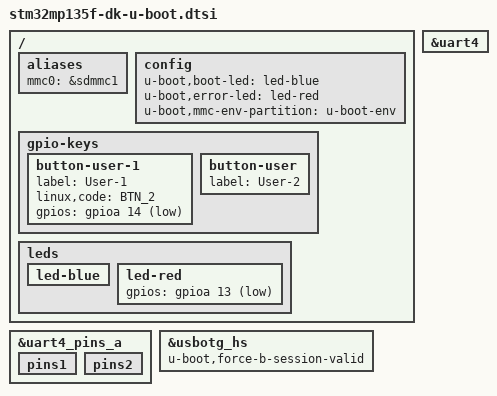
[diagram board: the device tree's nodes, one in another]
// SPDX-License-Identifier: GPL-2.0-or-later OR BSD-3-Clause
/*
 * Copyright (C) 2022, STMicroelectronics - All Rights Reserved
 */

#include "stm32mp13-u-boot.dtsi"

/ {
	aliases {
		mmc0 = &sdmmc1;
	};

	config {
		u-boot,boot-led = "led-blue";
		u-boot,error-led = "led-red";
		u-boot,mmc-env-partition = "u-boot-env";
	};

	gpio-keys {
		button-user-1 {
			label = "User-1";
			linux,code = <BTN_2>;
			gpios = <&gpioa 14 (GPIO_ACTIVE_LOW | GPIO_PULL_UP)>;
		};

		button-user {
			/* update label to match the label requested in board_key_check() */
			label = "User-2";
		};
	};

	leds {
		led-blue {
			/delete-property/default-state;
		};

		led-red {
			gpios = <&gpioa 13 GPIO_ACTIVE_LOW>;
		};
	};
};

&uart4 {
	bootph-all;
};

&uart4_pins_a {
	bootph-all;
	pins1 {
		bootph-all;
	};
	pins2 {
		bootph-all;
	};
};

&usbotg_hs {
	u-boot,force-b-session-valid;
};
